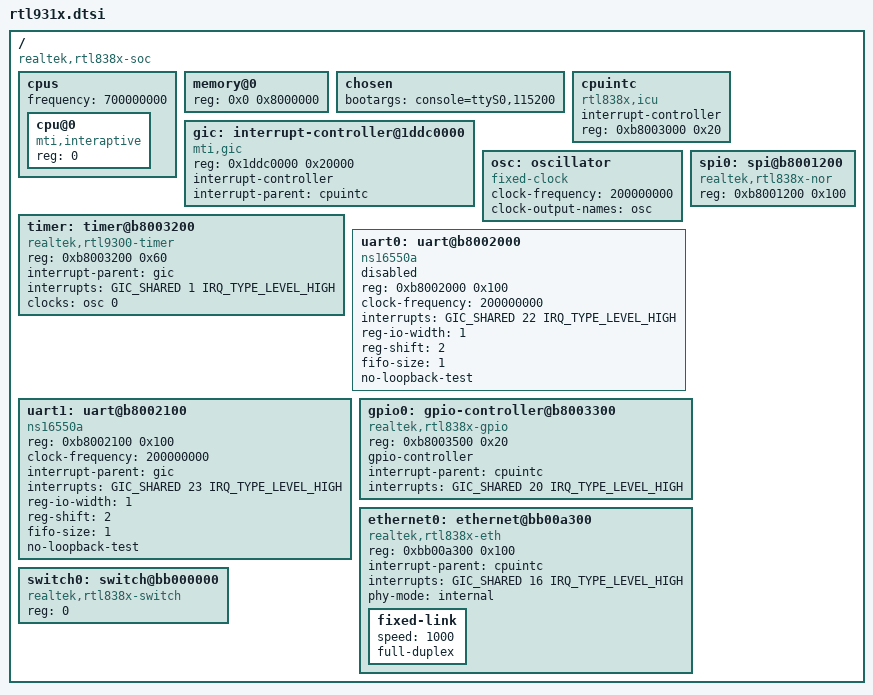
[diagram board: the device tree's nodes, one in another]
// SPDX-License-Identifier: GPL-2.0-or-later OR MIT

#include <dt-bindings/interrupt-controller/mips-gic.h>

/ {
	#address-cells = <1>;
	#size-cells = <1>;
	
	compatible = "realtek,rtl838x-soc";

	cpus {
		#address-cells = <1>;
		#size-cells = <0>;
		frequency = <700000000>;

		cpu@0 {
			// try: 
			compatible = "mti,interaptive";
			//compatible = "mips,mips34Kc";
			reg = <0>;
		};
	};

	memory@0 {
		device_type = "memory";
		reg = <0x0 0x8000000>;
	};
	
	chosen {
		bootargs = "console=ttyS0,115200";
	};

	cpuintc: cpuintc {
		#address-cells = <0>;
		#interrupt-cells = <1>;
		interrupt-controller;
		compatible = "rtl838x,icu";
		reg = <0xb8003000 0x20>;
	};

	gic: interrupt-controller@1ddc0000 {
		compatible = "mti,gic";
		reg = <0x1ddc0000 0x20000>;

		interrupt-controller;
		#interrupt-cells = <3>;

		/*
		 * Declare the interrupt-parent even though the mti,gic
		 * binding doesn't require it, such that the kernel can
		 * figure out that cpu_intc is the root interrupt
		 * controller & should be probed first.
		 */
		interrupt-parent = <&cpuintc>;
	};

	osc: oscillator {
		compatible = "fixed-clock";
		#clock-cells = <1>;
		clock-frequency  = <200000000>;
		clock-output-names = "osc";
	};

	timer: timer@b8003200 {
		compatible = "realtek,rtl9300-timer";
		reg = <0xb8003200 0x60>;
		interrupt-parent = <&gic>;
		interrupts = <GIC_SHARED 1 IRQ_TYPE_LEVEL_HIGH>;
		interrupt-names = "ostimer";
		clocks = <&osc 0>;
	};

	spi0: spi@b8001200 {
		status = "okay";

		compatible = "realtek,rtl838x-nor";
		reg = <0xb8001200 0x100>;

		#address-cells = <1>;
		#size-cells = <0>;
	};

	uart0: uart@b8002000 {
		compatible = "ns16550a";
		reg = <0xb8002000 0x100>;

		clock-frequency = <200000000>;
		interrupts = <GIC_SHARED 22 IRQ_TYPE_LEVEL_HIGH>;

		reg-io-width = <1>;
		reg-shift = <2>;
		fifo-size = <1>;
		no-loopback-test;

		status = "disabled";
	};

	uart1: uart@b8002100 {
		compatible = "ns16550a";
		reg = <0xb8002100 0x100>;

		clock-frequency = <200000000>;

		interrupt-parent = <&gic>;
		interrupts = <GIC_SHARED 23 IRQ_TYPE_LEVEL_HIGH>;

		reg-io-width = <1>;
		reg-shift = <2>;
		fifo-size = <1>;
		no-loopback-test;

		status = "okay";
	};

	gpio0: gpio-controller@b8003300 {
		compatible = "realtek,rtl838x-gpio";
		reg = <0xb8003500 0x20>;
		gpio-controller;
		#gpio-cells = <2>;
		interrupt-parent = <&cpuintc>;
		interrupts = <GIC_SHARED 20 IRQ_TYPE_LEVEL_HIGH>;
	};

	ethernet0: ethernet@bb00a300 {
		status = "okay";
		compatible = "realtek,rtl838x-eth";
		reg = <0xbb00a300 0x100>;
		interrupt-parent = <&cpuintc>;
		interrupts = <GIC_SHARED 16 IRQ_TYPE_LEVEL_HIGH>;
		#interrupt-cells = <1>;
		phy-mode = "internal";
		fixed-link {
			speed = <1000>;
			full-duplex;
		};
	};

	switch0: switch@bb000000 {
		status = "okay";
		compatible = "realtek,rtl838x-switch";
		reg = <0>;
	};
};
